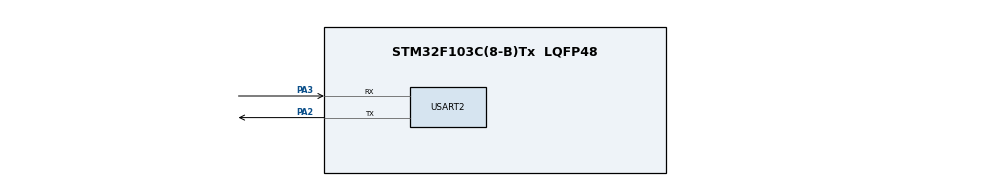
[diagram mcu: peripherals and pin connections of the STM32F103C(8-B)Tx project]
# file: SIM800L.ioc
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FREERTOS.Tasks01=defaultTask,0,128,StartDefaultTask,Default,NULL,Dynamic,NULL,NULL
Mcu.Family=STM32F1
Mcu.Name=STM32F103C(8-B)Tx
Mcu.Package=LQFP48
NVIC.PriorityGroup=NVIC_PRIORITYGROUP_4
NVIC.TIM1_UP_IRQn=true\:0\:0\:false\:false\:true\:false\:false\:true
NVIC.TimeBase=TIM1_UP_IRQn
NVIC.TimeBaseIP=TIM1
NVIC.USART2_IRQn=true\:10\:0\:true\:false\:true\:false\:true\:true
PA2.Mode=Asynchronous
PA2.Signal=USART2_TX
PA3.Mode=Asynchronous
PA3.Signal=USART2_RX
ProjectManager.HeapSize=0x200
ProjectManager.StackSize=0x400
ProjectManager.TargetToolchain=STM32CubeIDE
RCC.APB1Freq_Value=8000000
RCC.APB2Freq_Value=8000000
USART2.VirtualMode=VM_ASYNC
VP_FREERTOS_VS_CMSIS_V1.Mode=CMSIS_V1
VP_SYS_VS_ND.Mode=No_Debug
VP_SYS_VS_tim1.Mode=TIM1
board=custom

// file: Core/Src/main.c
/* USER CODE BEGIN Header */
/**
  ******************************************************************************
  * @file           : main.c
  * @brief          : Main program body
  ******************************************************************************
  * @attention
  *
  * <h2><center>&copy; Copyright (c) 2021 STMicroelectronics.
  * All rights reserved.</center></h2>
  *
  * This software component is licensed by ST under BSD 3-Clause license,
  * the "License"; You may not use this file except in compliance with the
  * License. You may obtain a copy of the License at:
  *                        opensource.org/licenses/BSD-3-Clause
  *
  ******************************************************************************
  */
/* USER CODE END Header */
#include "main.h"
#include "cmsis_os.h"
#include "usart.h"
#include "gpio.h"

/* USER CODE BEGIN Includes */
#include  "MQTTSim800.h"
/* USER CODE END Includes */

void SystemClock_Config(void);
void MX_FREERTOS_Init(void);

/* USER CODE BEGIN 0 */
     SIM800_t SIM800;

/* USER CODE END 0 */

int main(void)
{
  /* USER CODE BEGIN 1 */
	 SIM800.sim.apn = "internet";
	   SIM800.sim.apn_user = "";
	   SIM800.sim.apn_pass = "";
	   SIM800.mqttServer.host = "mqtt.mqtt.ru";
	   SIM800.mqttServer.port = 1883;
	   SIM800.mqttClient.username = "user";
	   SIM800.mqttClient.pass = "pass";
	   SIM800.mqttClient.clientID = "TestSub";
	   SIM800.mqttClient.keepAliveInterval = 120;
  /* USER CODE END 1 */

  /* MCU Configuration--------------------------------------------------------*/

  /* Reset of all peripherals, Initializes the Flash interface and the Systick. */
  HAL_Init();

  /* Configure the system clock */
  SystemClock_Config();

  /* Initialize all configured peripherals */
  MX_GPIO_Init();
  MX_USART2_UART_Init();

  /* Call init function for freertos objects (in freertos.c) */
  MX_FREERTOS_Init();
  /* Start scheduler */
  osKernelStart();

  /* We should never get here as control is now taken by the scheduler */
  /* Infinite loop */
  /* USER CODE BEGIN WHILE */

      MQTT_Init();
      uint8_t sub = 0;

 // ```
 // add a send topic "STM32" and value "test" to the server in an infinite while (1) loop, for example every 1 seconds.
 // add subscribe to topic "test"
 // ```
   /* Infinite loop */
   /* USER CODE BEGIN WHILE */
   while (1) {
       if (SIM800.mqttServer.connect == 0) {
           MQTT_Init();
           sub = 0;
       }
       if (SIM800.mqttServer.connect == 1) {
           if(sub == 0){
               MQTT_Sub("test");
               sub = 1;
           }
           MQTT_Pub("STM32", "test");

           if(SIM800.mqttReceive.newEvent) {
               unsigned char *topic = SIM800.mqttReceive.topic;
               int payload = atoi(SIM800.mqttReceive.payload);
               SIM800.mqttReceive.newEvent = 0;
           }
       }
       HAL_Delay(1000);

  /* USER CODE END 3 */
}
}

void SystemClock_Config(void)
{
  RCC_OscInitTypeDef RCC_OscInitStruct = {0};
  RCC_ClkInitTypeDef RCC_ClkInitStruct = {0};

  /** Initializes the RCC Oscillators according to the specified parameters
  * in the RCC_OscInitTypeDef structure.
  */
  RCC_OscInitStruct.OscillatorType = RCC_OSCILLATORTYPE_HSI;
  RCC_OscInitStruct.HSIState = RCC_HSI_ON;
  RCC_OscInitStruct.HSICalibrationValue = RCC_HSICALIBRATION_DEFAULT;
  RCC_OscInitStruct.PLL.PLLState = RCC_PLL_NONE;
  if (HAL_RCC_OscConfig(&RCC_OscInitStruct) != HAL_OK)
  {
    Error_Handler();
  }
  /** Initializes the CPU, AHB and APB buses clocks
  */
  RCC_ClkInitStruct.ClockType = RCC_CLOCKTYPE_HCLK|RCC_CLOCKTYPE_SYSCLK
                              |RCC_CLOCKTYPE_PCLK1|RCC_CLOCKTYPE_PCLK2;
  RCC_ClkInitStruct.SYSCLKSource = RCC_SYSCLKSOURCE_HSI;
  RCC_ClkInitStruct.AHBCLKDivider = RCC_SYSCLK_DIV1;
  RCC_ClkInitStruct.APB1CLKDivider = RCC_HCLK_DIV1;
  RCC_ClkInitStruct.APB2CLKDivider = RCC_HCLK_DIV1;

  if (HAL_RCC_ClockConfig(&RCC_ClkInitStruct, FLASH_LATENCY_0) != HAL_OK)
  {
    Error_Handler();
  }
}

void HAL_TIM_PeriodElapsedCallback(TIM_HandleTypeDef *htim)
{
  if (htim->Instance == TIM1) {
    HAL_IncTick();
  }
}

void Error_Handler(void)
{
}

/************************ (C) COPYRIGHT STMicroelectronics *****END OF FILE****/
